# STM32H747_CM4 register map
File version: 1.8
CPU: CM4 r0p1, little endian, MPU, FPU, 4 interrupt priority bits
Registers are 32-bit, read-write, reset 0x0 unless marked. A register's access mark holds for its fields unless they carry their own. Offsets are from the block's base; [hi:lo] are bit positions; {n}, {i} and the like mark numbered series.

## DMAMUX1 — DMAMUX
Base 0x40020800
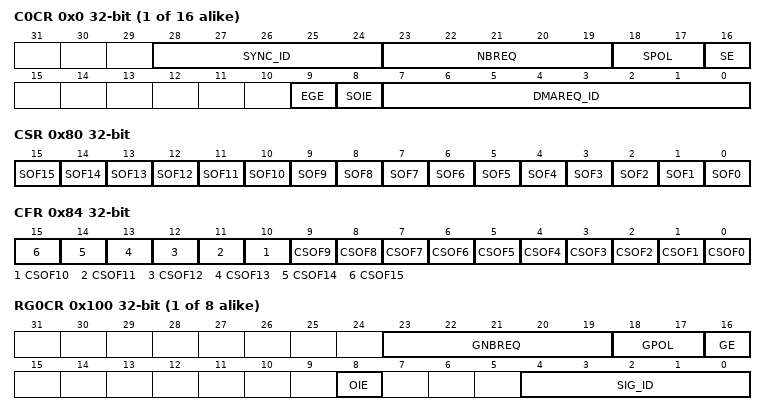
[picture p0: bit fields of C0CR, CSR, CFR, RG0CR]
{0x0+4i} C{i}CR (i=0..15) — DMAMux - DMA request line multiplexer channel x control register
  [28:24] SYNC_ID — Synchronization input selected
    0=dmamux1_evt0 (Signal `dmamux1_evt0` selected as synchronization input); 1=dmamux1_evt1 (Signal `dmamux1_evt1` selected as synchronization input); 2=dmamux1_evt2 (Signal `dmamux1_evt2` selected as synchronization input); 3=lptim1_out (Signal `lptim1_out` selected as synchronization input); 4=lptim2_out (Signal `lptim2_out` selected as synchronization input); 5=lptim3_out (Signal `lptim3_out` selected as synchronization input); 6=extit0 (Signal `extit0` selected as synchronization input); 7=tim12_trgo (Signal `tim12_trgo` selected as synchronization input)
  [23:19] NBREQ — Number of DMA requests to forward Defines the number of DMA requests forwarded before output event is generated. In synchronous mode, it also defines the number of DMA requests to forward after a synchronization event, then stop forwarding. The actual number of DMA requests forwarded is NBREQ+1. Note: This field can only be written when both SE and EGE bits are reset.
  [18:17] SPOL — Synchronization event type selector Defines the synchronization event on the selected synchronization input:
    0=NoEdge (No event, i.e. no synchronization nor detection); 1=RisingEdge; 2=FallingEdge; 3=BothEdges (Rising and falling edges)
  [16] SE — Synchronous operating mode enable/disable
    0=Disabled (Synchronization disabled); 1=Enabled (Synchronization enabled)
  [9] EGE — Event generation enable/disable
    0=Disabled (Event generation disabled); 1=Enabled (Event generation enabled)
  [8] SOIE — Interrupt enable at synchronization event overrun
    0=Disabled (Synchronization overrun interrupt disabled); 1=Enabled (Synchronization overrun interrupt enabled)
  [7:0] DMAREQ_ID — Input DMA request line selected
    0=none (No signal selected as request input); {v}=dmamux1_req_gen{v-1} (Signal `dmamux1_req_gen{v-1}` selected as request input) (v=1..8); 9=adc1_dma (Signal `adc1_dma` selected as request input); 10=adc2_dma (Signal `adc2_dma` selected as request input); {v}=tim1_ch{v-10} (Signal `tim1_ch{v-10}` selected as request input) (v=11..14); 15=tim1_up (Signal `tim1_up` selected as request input); 16=tim1_trig (Signal `tim1_trig` selected as request input); 17=tim1_com (Signal `tim1_com` selected as request input); {v}=tim2_ch{v-17} (Signal `tim2_ch{v-17}` selected as request input) (v=18..21); 22=tim2_up (Signal `tim2_up` selected as request input); {v}=tim3_ch{v-22} (Signal `tim3_ch{v-22}` selected as request input) (v=23..26); 27=tim3_up (Signal `tim3_up` selected as request input); 28=tim3_trig (Signal `tim3_trig` selected as request input); 29=tim4_ch1 (Signal `tim4_ch1` selected as request input); 30=tim4_ch2 (Signal `tim4_ch2` selected as request input); 31=tim4_ch3 (Signal `tim4_ch3` selected as request input); 32=tim4_up (Signal `tim4_up` selected as request input); 33=i2c1_rx_dma (Signal `i2c1_rx_dma` selected as request input); 34=i2c1_tx_dma (Signal `i2c1_tx_dma` selected as request input); 35=i2c2_rx_dma (Signal `i2c2_rx_dma` selected as request input); 36=i2c2_tx_dma (Signal `i2c2_tx_dma` selected as request input); 37=spi1_rx_dma (Signal `spi1_rx_dma` selected as request input); 38=spi1_tx_dma (Signal `spi1_tx_dma` selected as request input); 39=spi2_rx_dma (Signal `spi2_rx_dma` selected as request input); 40=spi2_tx_dma (Signal `spi2_tx_dma` selected as request input); 41=usart1_rx_dma (Signal `usart1_rx_dma` selected as request input); 42=usart1_tx_dma (Signal `usart1_tx_dma` selected as request input); 43=usart2_rx_dma (Signal `usart2_rx_dma` selected as request input); 44=usart2_tx_dma (Signal `usart2_tx_dma` selected as request input); 45=usart3_rx_dma (Signal `usart3_rx_dma` selected as request input); 46=usart3_tx_dma (Signal `usart3_tx_dma` selected as request input); {v}=tim8_ch{v-46} (Signal `tim8_ch{v-46}` selected as request input) (v=47..50); 51=tim8_up (Signal `tim8_up` selected as request input); 52=tim8_trig (Signal `tim8_trig` selected as request input); 53=tim8_com (Signal `tim8_com` selected as request input); {v}=tim5_ch{v-54} (Signal `tim5_ch{v-54}` selected as request input) (v=55..58); 59=tim5_up (Signal `tim5_up` selected as request input); 60=tim5_trig (Signal `tim5_trig` selected as request input); 61=spi3_rx_dma (Signal `spi3_rx_dma` selected as request input); 62=spi3_tx_dma (Signal `spi3_tx_dma` selected as request input); 63=uart4_rx_dma (Signal `uart4_rx_dma` selected as request input); 64=uart4_tx_dma (Signal `uart4_tx_dma` selected as request input); 65=uart5_rx_dma (Signal `uart5_rx_dma` selected as request input); 66=uart5_tx_dma (Signal `uart5_tx_dma` selected as request input); 67=dac_ch1_dma (Signal `dac_ch1_dma` selected as request input); 68=dac_ch2_dma (Signal `dac_ch2_dma` selected as request input); 69=tim6_up (Signal `tim6_up` selected as request input); 70=tim7_up (Signal `tim7_up` selected as request input); 71=usart6_rx_dma (Signal `usart6_rx_dma` selected as request input); 72=usart6_tx_dma (Signal `usart6_tx_dma` selected as request input); 73=i2c3_rx_dma (Signal `i2c3_rx_dma` selected as request input); 74=i2c3_tx_dma (Signal `i2c3_tx_dma` selected as request input); 75=dcmi_dma (Signal `dcmi_dma` selected as request input); 76=cryp_in_dma (Signal `cryp_in_dma` selected as request input); 77=cryp_out_dma (Signal `cryp_out_dma` selected as request input); 78=hash_in_dma (Signal `hash_in_dma` selected as request input); 79=uart7_rx_dma (Signal `uart7_rx_dma` selected as request input); 80=uart7_tx_dma (Signal `uart7_tx_dma` selected as request input); 81=uart8_rx_dma (Signal `uart8_rx_dma` selected as request input); 82=uart8_tx_dma (Signal `uart8_tx_dma` selected as request input); 83=spi4_rx_dma (Signal `spi4_rx_dma` selected as request input); 84=spi4_tx_dma (Signal `spi4_tx_dma` selected as request input); 85=spi5_rx_dma (Signal `spi5_rx_dma` selected as request input); 86=spi5_tx_dma (Signal `spi5_tx_dma` selected as request input); 87=sai1a_dma (Signal `sai1a_dma` selected as request input); 88=sai1b_dma (Signal `sai1b_dma` selected as request input); 89=sai2a_dma (Signal `sai2a_dma` selected as request input); 90=sai2b_dma (Signal `sai2b_dma` selected as request input); 91=swpmi_rx_dma (Signal `swpmi_rx_dma` selected as request input); 92=swpmi_tx_dma (Signal `swpmi_tx_dma` selected as request input); 93=spdifrx_dat_dma (Signal `spdifrx_dat_dma` selected as request input); 94=spdifrx_ctrl_dma (Signal `spdifrx_ctrl_dma` selected as request input); {v}=hr_req{v-94} (Signal `hr_req({v-94})` selected as request input) (v=95..100); {v}=dfsdm1_dma{v-101} (Signal `dfsdm1_dma{v-101}` selected as request input) (v=101..104); 105=tim15_ch1 (Signal `tim15_ch1` selected as request input); 106=tim15_up (Signal `tim15_up` selected as request input); 107=tim15_trig (Signal `tim15_trig` selected as request input); 108=tim15_com (Signal `tim15_com` selected as request input); 109=tim16_ch1 (Signal `tim16_ch1` selected as request input); 110=tim16_up (Signal `tim16_up` selected as request input); 111=tim17_ch1 (Signal `tim17_ch1` selected as request input); 112=tim17_up (Signal `tim17_up` selected as request input); 113=sai3_a_dma (Signal `sai3_a_dma` selected as request input); 114=sai3_b_dma (Signal `sai3_b_dma` selected as request input); 115=adc3_dma (Signal `adc3_dma` selected as request input)
0x80 CSR ro — DMAMUX request line multiplexer interrupt channel status register
  [n] SOF{n} (n=0..15) — Synchronization overrun event flag
    0=NoSyncEvent (No synchronization event occured on a DMA request line multiplexer channel x, while the DMA request counter value is lower than NBREQ); 1=SyncEvent (Synchronization event occured on a DMA request line multiplexer channel x, while the DMA request counter value is lower than NBREQ)
0x84 CFR wo — DMAMUX request line multiplexer interrupt clear flag register
  [n] CSOF{n} (n=0..15) write-1-clears — Clear synchronization overrun event flag
    1=Clear synchronization flag
{0x100+4i} RG{i}CR (i=0..7) — DMAMux - DMA request generator channel x control register
  [23:19] GNBREQ — Number of DMA requests to generate Defines the number of DMA requests generated after a trigger event, then stop generating. The actual number of generated DMA requests is GNBREQ+1. Note: This field can only be written when GE bit is reset.
  [18:17] GPOL — DMA request generator trigger event type selection Defines the trigger event on the selected DMA request trigger input
    0=NoEdge (No event, i.e. no detection nor generation); 1=RisingEdge; 2=FallingEdge; 3=BothEdges (Rising and falling edges)
  [16] GE — DMA request generator channel enable/disable
    0=Disabled (DMA request generation disabled); 1=Enabled (DMA request enabled)
  [8] OIE — Interrupt enable at trigger event overrun
    0=Disabled (Trigger overrun interrupt disabled); 1=Enabled (Trigger overrun interrupt enabled)
  [4:0] SIG_ID — DMA request trigger input selected
    0=dmamux1_evt0 (Signal `dmamux1_evt0` selected as trigger input); 1=dmamux1_evt1 (Signal `dmamux1_evt1` selected as trigger input); 2=dmamux1_evt2 (Signal `dmamux1_evt2` selected as trigger input); 3=lptim1_out (Signal `lptim1_out` selected as trigger input); 4=lptim2_out (Signal `lptim2_out` selected as trigger input); 5=lptim3_out (Signal `lptim3_out` selected as trigger input); 6=extit0 (Signal `extit0` selected as trigger input); 7=tim12_trgo (Signal `tim12_trgo` selected as trigger input)
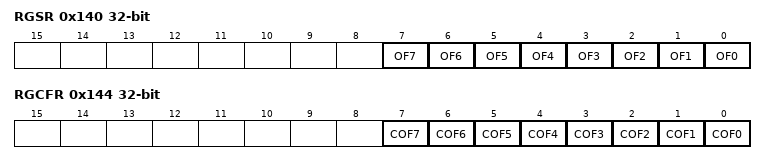
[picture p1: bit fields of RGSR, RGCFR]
0x140 RGSR ro — DMAMux - DMA request generator status register
  [n] OF{n} (n=0..7) — Trigger event overrun flag The flag is set when a trigger event occurs on DMA request generator channel x, while the DMA request generator counter value is lower than GNBREQ. The flag is cleared by writing 1 to the corresponding COFx bit in DMAMUX_RGCFR register.
    0=NoTrigger (No new trigger event occured on DMA request generator channel x, before the request counter underrun); 1=Trigger (New trigger event occured on DMA request generator channel x, before the request counter underrun)
0x144 RGCFR wo — DMAMux - DMA request generator clear flag register
  [n] COF{n} (n=0..7) write-1-clears — Clear trigger event overrun flag Upon setting, this bit clears the corresponding overrun flag OFx in the DMAMUX_RGCSR register.
    1=Clear overrun flag
